# AVR32LA32 device description
Architecture: AVR8X; Family: AVR
Registers are 8-bit, read-write, reset 0x0 unless marked. A register's access mark holds for its fields unless they carry their own. Offsets are from the block's base; [hi:lo] are bit positions; {n}, {i} and the like mark numbered series; 'fields as' and 'values as' point back to an identical list.

## EVSYS — Event System
Instances: EVSYS 0x0200
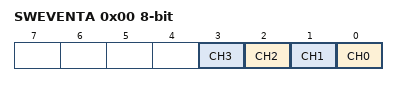
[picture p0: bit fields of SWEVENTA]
0x00 SWEVENTA wo — Software Event A
  [n] CH{n} (n=0..3) — Channel {n} Select
{0x10+i} CHANNEL{i} (i=0..3) — Multiplexer Channel {i}
  [7:0] CHANNEL — Channel Generator Select
    0=OFF; 1=UPDI_SYNCH (UPDI SYNCH character); 6=RTC_OVF (Real Time Counter overflow); 7=RTC_CMP (Real Time Counter compare); 8=RTC_EVGEN0 (Selectable prescaled RTC Event 0); 9=RTC_EVGEN1 (Selectable prescaled RTC Event 1); {v}=CCL_LUT{v-16} (Configurable Custom Logic LUT{v-16}) (v=16..19); 32=AC0_OUT (Analog Comparator 0 out); 36=ADC0_RES (ADC 0 Result Ready); 37=ADC0_SAMP (ADC 0 Sample Ready); 38=ADC0_WCMP (ADC 0 Window Compare); 64=PORTA_EVGEN0 (Port A Event 0); 65=PORTA_EVGEN1 (Port A Event 1); 68=PORTC_EVGEN0 (Port C Event 0); 69=PORTC_EVGEN1 (Port C Event 1); 70=PORTD_EVGEN0 (Port D Event 0); 71=PORTD_EVGEN1 (Port D Event 1); 74=PORTF_EVGEN0 (Port F Event 0); 75=PORTF_EVGEN1 (Port F Event 1); 96=USART0_XCK; 104=SPI0_SCK; 128=TCE0_OVF (Timer/Counter E0 overflow); 132=TCE0_CMP0 (Timer/Counter E0 compare 0); 133=TCE0_CMP1 (Timer/Counter E0 compare 1); 134=TCE0_CMP2 (Timer/Counter E0 compare 2); 160=TCB0_CAPT (Timer/Counter B0 capture); 161=TCB0_OVF (Timer/Counter B0 overflow); 162=TCB1_CAPT (Timer/Counter B1 capture); 163=TCB1_OVF (Timer/Counter B1 overflow)
0x20 USERCCLLUT0A — User 0 - CCL LUT0 Event A
  [7:0] USER — User channel select
    0=OFF; {v}=CHANNEL{v-1} (Connect user to event channel {v-1}) (v=1..4)
0x21 USERCCLLUT0B — User 1 - CCL LUT0 Event B
  fields as USERCCLLUT0A
0x22 USERCCLLUT1A — User 2 - CCL LUT1 Event A
  fields as USERCCLLUT0A
0x23 USERCCLLUT1B — User 3 - CCL LUT1 Event B
  fields as USERCCLLUT0A
0x24 USERAC0SAMPLE — User 4 - AC0
  fields as USERCCLLUT0A
0x25 USERADC0START — User 5 - ADC0
  fields as USERCCLLUT0A
0x26 USEREVSYSEVOUTA — User 6 - EVOUTA
  fields as USERCCLLUT0A
0x27 USEREVSYSEVOUTC — User 7 - EVOUTC
  fields as USERCCLLUT0A
0x28 USEREVSYSEVOUTD — User 8 - EVOUTD
  fields as USERCCLLUT0A
0x29 USEREVSYSEVOUTF — User 9 - EVOUTF
  fields as USERCCLLUT0A
0x2A USERUSART0RXD — User 10 - USART0 RxD Event Input
  fields as USERCCLLUT0A
0x2B USERTCE0CNTA — User 11 - TCE0 Count A
  fields as USERCCLLUT0A
0x2C USERTCE0CNTB — User 12 - TCE0 Count B
  fields as USERCCLLUT0A
0x2D USERTCB0CAPT — User 13 - TCB0 Capture
  fields as USERCCLLUT0A
0x2E USERTCB0COUNT — User 14 - TCB0 Count
  fields as USERCCLLUT0A
0x2F USERTCB1CAPT — User 15 - TCB1 Capture
  fields as USERCCLLUT0A
0x30 USERTCB1COUNT — User 16 - TCB1 Count
  fields as USERCCLLUT0A

## FUSE — Fuses
Instances: FUSE 0x1050
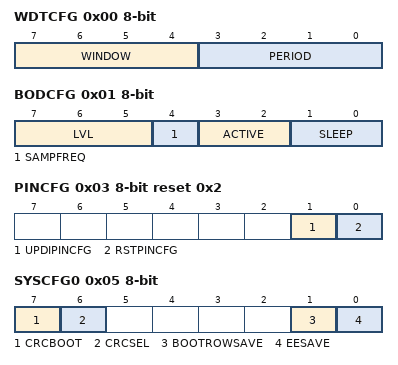
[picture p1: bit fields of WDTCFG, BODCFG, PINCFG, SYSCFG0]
0x00 WDTCFG — Watchdog Configuration
  [7:4] WINDOW — Watchdog Window Timeout Period
    0=OFF; 1=8CLK (8 cycles (8ms)); 2=16CLK (16 cycles (16ms)); 3=32CLK (32 cycles (32ms)); 4=64CLK (64 cycles (64ms)); 5=128CLK (128 cycles (0.128s)); 6=256CLK (256 cycles (0.256s)); 7=512CLK (512 cycles (0.512s)); 8=1KCLK (1K cycles (1.0s)); 9=2KCLK (2K cycles (2.0s)); 10=4KCLK (4K cycles (4.1s)); 11=8KCLK (8K cycles (8.2s))
  [3:0] PERIOD — Watchdog Timeout Period
    values as WINDOW
0x01 BODCFG — BOD Configuration
  [7:5] LVL — BOD Level
    0=BODLEVEL0 (1.65 V); 1=BODLEVEL1 (1.90 V); 2=BODLEVEL2 (2.60 V); 3=BODLEVEL3 (4.30 V)
  [4] SAMPFREQ — BOD Sample Frequency
    0=128HZ (Sampling frequency is 128 Hz); 1=32HZ (Sample frequency is 32 Hz)
  [3:2] ACTIVE — BOD Operation in Active Mode
    0=DISABLE (Disabled); 1=ENABLE (Enabled in continuous mode); 2=SAMPLE (Enabled in sampled mode); 3=ENABLEWAIT (Enabled in continuous mode. Execution halted at wake-up until BOD is running)
  [1:0] SLEEP — BOD Operation in Sleep Mode
    0=DISABLE (Disabled); 1=ENABLE (Enabled in continuous mode); 2=SAMPLE (Enabled in sampled mode)
0x02 OSCCFG — Oscillator Configuration
  [3] OSCHFFRQ — High-frequency Oscillator Frequency
    0=20M (OSCHF running at 20 MHz); 1=16M (OSCHF running at 16 MHz)
0x03 PINCFG reset 0x2 — Pin Configuration
  [1] UPDIPINCFG — UPDI Pin Configuration select
    0=GPIO (PF7 configures as GPIO pin); 1=UPDI (PF7 configures as UPDI pin)
  [0] RSTPINCFG — Reset Pin Configuration select
    0=INPUT (PF6 configures as INPUT pin); 1=RESET (PF6 configures as RESET pin)
0x04 HVMONCFG — Hardware Monitor Configuration
  [0] CPUMON — CPU Monitor
0x05 SYSCFG0 — System Configuration 0
  [7] CRCBOOT — CRC Check on Boot
  [6] CRCSEL — CRC Select
    0=CRC16 (Enable CRC16); 1=CRC32 (Enable CRC32)
  [1] BOOTROWSAVE
  [0] EESAVE — EEPROM Save
0x06 SYSCFG1 reset 0x7 — System Configuration 1
  [2:0] SUT — Startup Time
    0=0MS; 1=1MS; 2=2MS; 3=4MS; 4=8MS; 5=16MS; 6=32MS; 7=64MS
0x07 CODESIZE — Code Section Size
0x08 BOOTSIZE — Boot Section Size
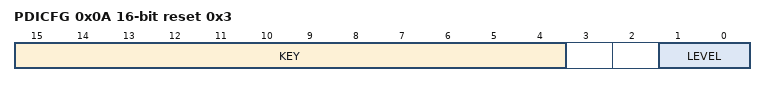
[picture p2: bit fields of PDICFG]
0x0A PDICFG 16-bit reset 0x3 — UPDI Protection
  [15:4] KEY — NVM Protection Activation Key
    0=NOTACT (Not active); 0xB45=NVMACT (NVM protection active. Chip erase is disabled.)
  [1:0] LEVEL — Protection Level
    2=NVMACCDIS (NVM Access through UPDI disabled); 3=BASIC (UPDI interface is enabled)
